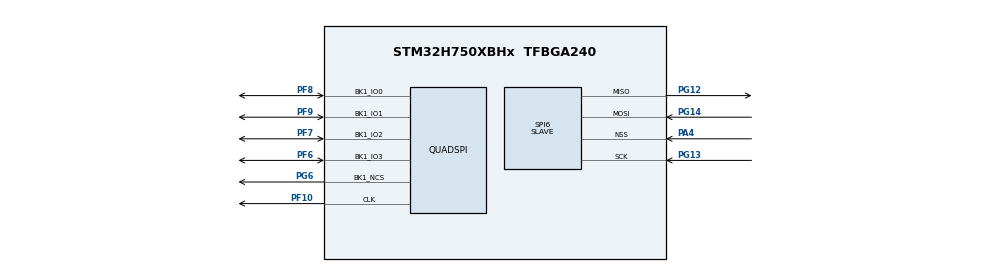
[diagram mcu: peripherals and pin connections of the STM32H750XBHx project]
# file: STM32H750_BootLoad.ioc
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CORTEX_M7.CPU_DCache=Disabled
CORTEX_M7.CPU_ICache=Disabled
Mcu.Family=STM32H7
Mcu.Name=STM32H750XBHx
Mcu.Package=TFBGA240
NVIC.PriorityGroup=NVIC_PRIORITYGROUP_4
PA13\ (JTMS/SWDIO).Mode=Serial_Wire
PA13\ (JTMS/SWDIO).Signal=DEBUG_JTMS-SWDIO
PA14\ (JTCK/SWCLK).Mode=Serial_Wire
PA14\ (JTCK/SWCLK).Signal=DEBUG_JTCK-SWCLK
PA4.GPIO_Speed=GPIO_SPEED_FREQ_VERY_HIGH
PA4.Mode=NSS_Signal_Hard_Input
PA4.Signal=SPI6_NSS
PC14-OSC32_IN\ (OSC32_IN).Mode=LSE-External-Oscillator
PC14-OSC32_IN\ (OSC32_IN).Signal=RCC_OSC32_IN
PC15-OSC32_OUT\ (OSC32_OUT).Mode=LSE-External-Oscillator
PC15-OSC32_OUT\ (OSC32_OUT).Signal=RCC_OSC32_OUT
PF10.GPIO_Speed=GPIO_SPEED_FREQ_VERY_HIGH
PF10.Mode=Single Bank 1
PF10.Signal=QUADSPI_CLK
PF6.GPIO_Speed=GPIO_SPEED_FREQ_VERY_HIGH
PF6.Mode=Single Bank 1
PF6.Signal=QUADSPI_BK1_IO3
PF7.GPIO_Speed=GPIO_SPEED_FREQ_VERY_HIGH
PF7.Mode=Single Bank 1
PF7.Signal=QUADSPI_BK1_IO2
PF8.GPIO_Speed=GPIO_SPEED_FREQ_VERY_HIGH
PF8.Mode=Single Bank 1
PF8.Signal=QUADSPI_BK1_IO0
PF9.GPIO_Speed=GPIO_SPEED_FREQ_VERY_HIGH
PF9.Mode=Single Bank 1
PF9.Signal=QUADSPI_BK1_IO1
PG12.GPIO_Speed=GPIO_SPEED_FREQ_VERY_HIGH
PG12.Mode=Full_Duplex_Slave
PG12.Signal=SPI6_MISO
PG13.GPIO_Speed=GPIO_SPEED_FREQ_VERY_HIGH
PG13.Mode=Full_Duplex_Slave
PG13.Signal=SPI6_SCK
PG14.GPIO_Speed=GPIO_SPEED_FREQ_VERY_HIGH
PG14.Mode=Full_Duplex_Slave
PG14.Signal=SPI6_MOSI
PG6.GPIO_Speed=GPIO_SPEED_FREQ_VERY_HIGH
PG6.Mode=Single Bank 1
PG6.Signal=QUADSPI_BK1_NCS
PH0-OSC_IN\ (PH0).Mode=HSE-External-Oscillator
PH0-OSC_IN\ (PH0).Signal=RCC_OSC_IN
PH1-OSC_OUT\ (PH1).Mode=HSE-External-Oscillator
PH1-OSC_OUT\ (PH1).Signal=RCC_OSC_OUT
ProjectManager.HeapSize=0x200
ProjectManager.StackSize=0x400
ProjectManager.TargetToolchain=MDK-ARM V5.32
QUADSPI.ClockMode=QSPI_CLOCK_MODE_3
QUADSPI.ClockPrescaler=1
QUADSPI.FifoThreshold=32
QUADSPI.FlashSize=22
QUADSPI.SampleShifting=QSPI_SAMPLE_SHIFTING_HALFCYCLE
RCC.ADCFreq_Value=50390625
RCC.APB1Freq_Value=120000000
RCC.APB2Freq_Value=120000000
RCC.APB3Freq_Value=120000000
RCC.APB4Freq_Value=120000000
RCC.CortexFreq_Value=480000000
RCC.D1PPRE=RCC_APB3_DIV2
RCC.D2PPRE1=RCC_APB1_DIV2
RCC.D2PPRE2=RCC_APB2_DIV2
RCC.D3PPRE=RCC_APB4_DIV2
RCC.DIVM1=5
RCC.DIVN1=192
RCC.HCLKFreq_Value=240000000
RCC.HPRE=RCC_HCLK_DIV2
RCC.PLLFRACN=0
RCC.PLLSourceVirtual=RCC_PLLSOURCE_HSE
RCC.SYSCLKFreq_VALUE=480000000
RCC.SYSCLKSource=RCC_SYSCLKSOURCE_PLLCLK
RCC.USBFreq_Value=480000000
SPI6.DataSize=SPI_DATASIZE_8BIT
SPI6.Direction=SPI_DIRECTION_2LINES
SPI6.Mode=SPI_MODE_SLAVE
SPI6.VirtualNSS=VM_NSSHARD
SPI6.VirtualType=VM_SLAVE
board=custom

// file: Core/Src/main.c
/* USER CODE BEGIN Header */
/**
  ******************************************************************************
  * @file           : main.c
  * @brief          : Main program body
  ******************************************************************************
  * @attention
  *
  * Copyright (c) 2024 STMicroelectronics.
  * All rights reserved.
  *
  * This software is licensed under terms that can be found in the LICENSE file
  * in the root directory of this software component.
  * If no LICENSE file comes with this software, it is provided AS-IS.
  *
  ******************************************************************************
  */
/* USER CODE END Header */
#include "main.h"
#include "quadspi.h"
#include "spi.h"
#include "gpio.h"

/* USER CODE BEGIN Includes */
#include "qspi_w25q64.h"
/* USER CODE END Includes */

void SystemClock_Config(void);

/* USER CODE BEGIN 0 */
typedef  void (*pFunction)(void);

pFunction JumpToApplication;

/* USER CODE END 0 */

int main(void)
{

  /* MCU Configuration--------------------------------------------------------*/

  /* Reset of all peripherals, Initializes the Flash interface and the Systick. */
  HAL_Init();

  /* Configure the system clock */
  SystemClock_Config();

  /* Initialize all configured peripherals */
  MX_GPIO_Init();
  MX_QUADSPI_Init();
  MX_SPI6_Init();
  /* USER CODE BEGIN 2 */
	QSPI_W25Qxx_Init();
	QSPI_W25Qxx_MemoryMappedMode();
	SysTick->CTRL = 0;		// 关闭SysTick
	SysTick->LOAD = 0;		// 清零重载�?
	SysTick->VAL = 0;			// 清零计数�?

	JumpToApplication = (pFunction) (*(__IO uint32_t*) (W25Qxx_Mem_Addr + 4));	// 设置起始地址
	__set_MSP(*(__IO uint32_t*) W25Qxx_Mem_Addr);	// 设置主堆栈指�?
	//printf("跳转到W25Q64运行用户程序>>>\r\n\r\n");

	JumpToApplication();			// 执行跳转

  /* USER CODE END 2 */

  /* Infinite loop */
  while (1)
  {

  }
}

void SystemClock_Config(void)
{
  RCC_OscInitTypeDef RCC_OscInitStruct = {0};
  RCC_ClkInitTypeDef RCC_ClkInitStruct = {0};

  /** Supply configuration update enable
  */
  HAL_PWREx_ConfigSupply(PWR_LDO_SUPPLY);

  /** Configure the main internal regulator output voltage
  */
  __HAL_PWR_VOLTAGESCALING_CONFIG(PWR_REGULATOR_VOLTAGE_SCALE1);

  while(!__HAL_PWR_GET_FLAG(PWR_FLAG_VOSRDY)) {}

  __HAL_RCC_SYSCFG_CLK_ENABLE();
  __HAL_PWR_VOLTAGESCALING_CONFIG(PWR_REGULATOR_VOLTAGE_SCALE0);

  while(!__HAL_PWR_GET_FLAG(PWR_FLAG_VOSRDY)) {}

  /** Initializes the RCC Oscillators according to the specified parameters
  * in the RCC_OscInitTypeDef structure.
  */
  RCC_OscInitStruct.OscillatorType = RCC_OSCILLATORTYPE_HSE;
  RCC_OscInitStruct.HSEState = RCC_HSE_ON;
  RCC_OscInitStruct.PLL.PLLState = RCC_PLL_ON;
  RCC_OscInitStruct.PLL.PLLSource = RCC_PLLSOURCE_HSE;
  RCC_OscInitStruct.PLL.PLLM = 5;
  RCC_OscInitStruct.PLL.PLLN = 192;
  RCC_OscInitStruct.PLL.PLLP = 2;
  RCC_OscInitStruct.PLL.PLLQ = 2;
  RCC_OscInitStruct.PLL.PLLR = 2;
  RCC_OscInitStruct.PLL.PLLRGE = RCC_PLL1VCIRANGE_2;
  RCC_OscInitStruct.PLL.PLLVCOSEL = RCC_PLL1VCOWIDE;
  RCC_OscInitStruct.PLL.PLLFRACN = 0;
  if (HAL_RCC_OscConfig(&RCC_OscInitStruct) != HAL_OK)
  {
    Error_Handler();
  }

  /** Initializes the CPU, AHB and APB buses clocks
  */
  RCC_ClkInitStruct.ClockType = RCC_CLOCKTYPE_HCLK|RCC_CLOCKTYPE_SYSCLK
                              |RCC_CLOCKTYPE_PCLK1|RCC_CLOCKTYPE_PCLK2
                              |RCC_CLOCKTYPE_D3PCLK1|RCC_CLOCKTYPE_D1PCLK1;
  RCC_ClkInitStruct.SYSCLKSource = RCC_SYSCLKSOURCE_PLLCLK;
  RCC_ClkInitStruct.SYSCLKDivider = RCC_SYSCLK_DIV1;
  RCC_ClkInitStruct.AHBCLKDivider = RCC_HCLK_DIV2;
  RCC_ClkInitStruct.APB3CLKDivider = RCC_APB3_DIV2;
  RCC_ClkInitStruct.APB1CLKDivider = RCC_APB1_DIV2;
  RCC_ClkInitStruct.APB2CLKDivider = RCC_APB2_DIV2;
  RCC_ClkInitStruct.APB4CLKDivider = RCC_APB4_DIV2;

  if (HAL_RCC_ClockConfig(&RCC_ClkInitStruct, FLASH_LATENCY_4) != HAL_OK)
  {
    Error_Handler();
  }
}

void Error_Handler(void)
{
  __disable_irq();
  while (1)
  {
  }
}
